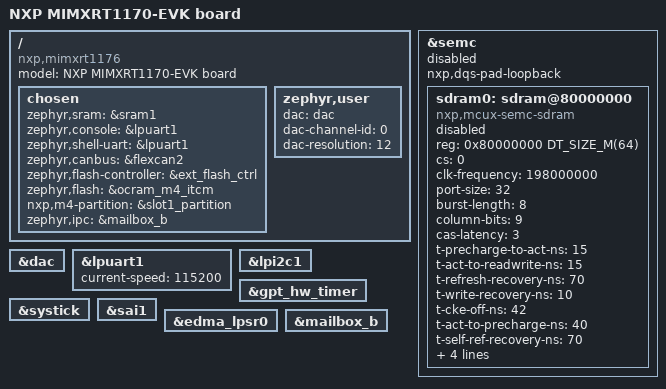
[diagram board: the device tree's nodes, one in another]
/*
 * Copyright 2021,2023 NXP
 *
 * SPDX-License-Identifier: Apache-2.0
 */

/dts-v1/;

#include <nxp/imxrt/imxrt11xx/nxp_rt1170_cm4.dtsi>
#include "mimxrt1170_evk.dtsi"

/ {
	model = "NXP MIMXRT1170-EVK board";
	compatible = "nxp,mimxrt1176";

	chosen {
		/*
		 * Note: when using DMA, the SRAM region must be set to
		 * a memory region that is not cached by the chip. If the chosen
		 * sram region is changed and DMA is in use, you will
		 * encounter issues!
		 */
		zephyr,sram = &sram1;
		zephyr,console = &lpuart1;
		zephyr,shell-uart = &lpuart1;
		zephyr,canbus = &flexcan2;
		zephyr,flash-controller = &ext_flash_ctrl;
		zephyr,flash = &ocram_m4_itcm;
		nxp,m4-partition = &slot1_partition;
		zephyr,ipc = &mailbox_b;
	};

	zephyr,user {
		dac = <&dac>;
		dac-channel-id = <0>;
		dac-resolution = <12>;
	};
};

&semc {
	status = "disabled";
	nxp,dqs-pad-loopback;

	sdram0: sdram@80000000 {
		/* Winbond W9825G6KH-5I */
		compatible = "nxp,mcux-semc-sdram";
		device_type = "memory";
		reg = <0x80000000 DT_SIZE_M(64)>;
		status = "disabled";
		cs = <0>;
		clk-frequency = <198000000>;
		port-size = <32>;
		burst-length = <8>;
		column-bits = <9>;
		cas-latency = <3>;
		t-precharge-to-act-ns = <15>;
		t-act-to-readwrite-ns = <15>;
		t-refresh-recovery-ns = <70>;
		t-write-recovery-ns = <10>;
		t-cke-off-ns = <42>;
		t-act-to-precharge-ns = <40>;
		t-self-ref-recovery-ns = <70>;
		t-refresh-to-refresh-ns = <60>;
		t-act-to-act-ns = <10>;
		refresh-period-ns-per-row = <7812>;
		delay-chain = <6>;
	};
};

&dac {
	status = "okay";
};

&lpuart1 {
	status = "okay";
	current-speed = <115200>;
};

&lpi2c1 {
	status = "okay";
};

/* GPT and Systick are enabled. If power management is enabled, the GPT
 * timer will be used instead of systick, as allows the core clock to
 * be gated.
 */
&gpt_hw_timer {
	status = "okay";
};

&systick {
	status = "okay";
};

&sai1 {
	status = "okay";
};

&edma_lpsr0 {
	status = "okay";
};

&mailbox_b {
	status = "okay";
};
